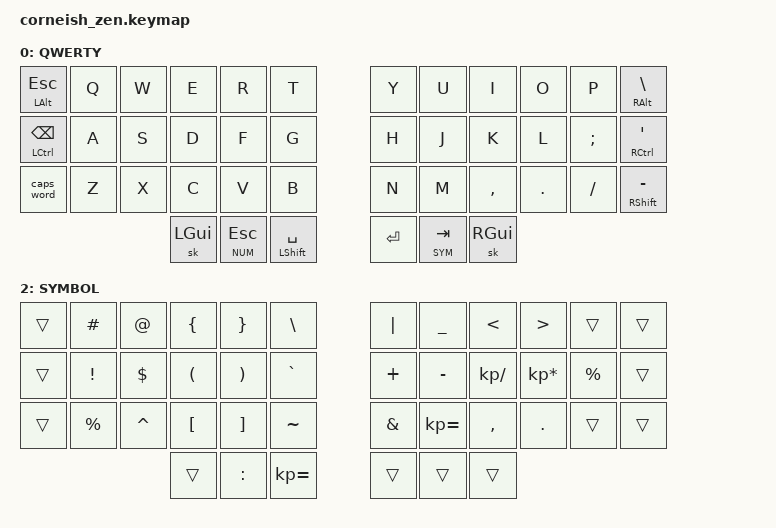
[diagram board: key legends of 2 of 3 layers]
#include <behaviors.dtsi>
#include <dt-bindings/zmk/keys.h>
#include <dt-bindings/zmk/bt.h>

#define QWE 0
#define NUM 1
#define SYM 2
/ {
  chosen {
    zmk,matrix_transform = &default_transform;
    //zmk,matrix_transform = &five_column_transform;
  };
};

/ {
        behaviors {
            gqt: global-quick-tap {
                compatible = "zmk,behavior-hold-tap";
                label = "GLOBAL_QUICK_TAP";
                #binding-cells = <2>;
                flavor = "tap-preferred";
                tapping-term-ms = <200>;
                quick-tap-ms = <135>;
                global-quick-tap;
                bindings= <&kp>, <&kp>;
            };
            bht: balanced_hold_tap {
                compatible = "zmk,behavior-hold-tap";
                label = "BALANCED HOLD TAP";
                #binding-cells = <2>;
                flavor = "balanced";
                tapping-term-ms = <200>;
                bindings = <&kp>, <&kp>;
            };
        };
        keymap {
                compatible = "zmk,keymap";

                default_layer {
                        label = "QWERTY";
// -----------------------------------------------------------------------------------------
// | Alt/TAB |  Q  |  W  |  E  |  R  |  T  |   |  A  |  U   |  I  |  O  |  P  | Alt/\|  |
// | CTRL/BS |  A  |  S  |  D  |  F  |  G  |   |  H  |  J   |  K  |  L  |  ;  | CTRL/'  |
// |   SHFT  |  Z  |  X  |  C  |  V  |  B  |   |  N  |  M   |  ,  |  .  |  /  | SHIFT/-_|
//                   | GUI | ESC/LWR | SPC |   | ENT | RSE  | GUI |
                        bindings = <
   &mt LALT ESC &kp Q &kp W &kp E &kp R &kp T   &kp Y &kp U  &kp I     &kp O   &kp P    &mt RALT BSLH
   &gqt LCTRL BSPC &kp A &kp S &kp D &kp F &kp G   &kp H &kp J  &kp K     &kp L   &kp SEMI &gqt RCTRL SINGLE_QUOTE
   &caps_word &kp Z &kp X &kp C &kp V &kp B   &kp N &kp M  &kp COMMA &kp DOT &kp FSLH &mt RSHIFT MINUS
                  &sk LGUI &lt NUM ESC &gqt LSHIFT SPACE   &kp RET &lt SYM TAB &sk RGUI
                        >;
                };
                lower_layer {
                        label = "NUMBER";
// -----------------------------------------------------------------------------------------
// |      |  1  |  2  |  3  |  4  |  5  |   | BT1 | BT2 | BT3 | BT4 | BT5 |BT CLR|
// |      |  6  |  7  |  8  |  9  |  0  |   |Left |Down |  Up |Right|     |      |
// |      |     |     |     |     |     |   |HOME |PGDN |PGUP | END |     |      |
//                    |     |     |     |   |  .  |     |     |
                        bindings = <
   &kp C_VOL_UP &kp N1 &kp N2 &kp N3 &kp N4 &kp N5     &bt BT_SEL 0 &bt BT_SEL 1 &bt BT_SEL 2 &bt BT_SEL 3 &bt BT_SEL 4 &bt BT_CLR
   &kp C_VOL_DN &kp N6 &kp N7 &kp N8 &kp N9 &kp N0     &kp LEFT &kp DOWN &kp UP &kp RIGHT &kp &trans &trans
   &kp C_MUTE  &trans &trans &trans &trans &trans      &kp HOME &kp PG_DN &kp PG_UP &kp END &trans &trans
                              &trans &trans &trans     &kp DOT &none &trans 
                        >;
                };

                raise_layer {
                        label = "SYMBOL";
// -----------------------------------------------------------------------------------------
// |      |  !  |  @  |  {  |  }  |  \  |   |  |  |  _  |  <  |  >  |     |      |
// |      |  $  |  $  |  (  |  )  |  `  |   | =/+ | -/_ |  /  |  *  |  %  |      |
// |      |  %  |  ^  |  [  |  ]  |  ~  |   |  &  |  =  |  ,  |  .  |     |      |
//                    |     |  :  |  =  |   |     |     |     |
                        bindings = <
   &trans &kp HASH &kp AT &kp LBRC &kp RBRC &kp BSLH           &kp PIPE &kp UNDER &kp LT &kp GT &trans &trans
   &trans &kp EXCL &kp DLLR &kp LPAR &kp RPAR &kp GRAVE        &kp PLUS &kp MINUS &kp KP_DIVIDE &kp KP_MULTIPLY &kp PERCENT &trans
   &trans &kp PERCENT &kp CARET &kp LBKT &kp RBKT &kp TILDE    &kp AMPS &kp KP_EQUAL &kp COMMA &kp DOT &trans &trans
                        &trans &kp COLON &kp KP_EQUAL             &trans &trans &trans
                        >;
                };
        };
};
